AUTOSAR XML (schema 00046)
package /ComponentTypes
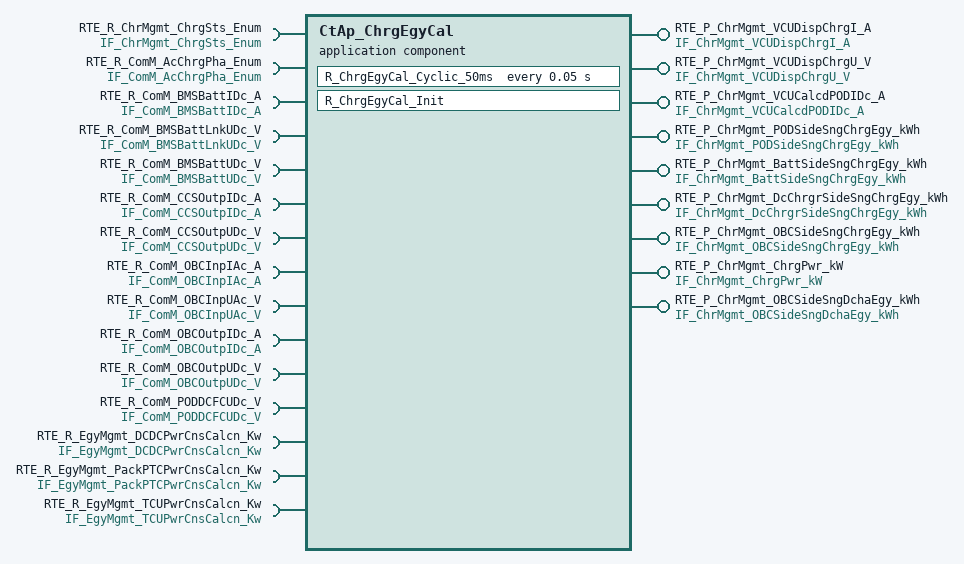
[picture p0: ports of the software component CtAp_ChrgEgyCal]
  application sw component type CtAp_ChrgEgyCal
    9 x provide port:
      RTE_P_ChrMgmt_VCUDispChrgI_A: nonqueued-sender-com-spec{data-element=tec_ChrMgmt_VCUDispChrgI_A, init-value=0}, provided-interface=IF_ChrMgmt_VCUDispChrgI_A
      RTE_P_ChrMgmt_VCUDispChrgU_V: nonqueued-sender-com-spec{data-element=tec_ChrMgmt_VCUDispChrgU_V, init-value=0}, provided-interface=IF_ChrMgmt_VCUDispChrgU_V
      RTE_P_ChrMgmt_VCUCalcdPODIDc_A: nonqueued-sender-com-spec{data-element=tec_ChrMgmt_VCUCalcdPODIDc_A, init-value=0}, provided-interface=IF_ChrMgmt_VCUCalcdPODIDc_A
      RTE_P_ChrMgmt_PODSideSngChrgEgy_kWh: nonqueued-sender-com-spec{data-element=tec_ChrMgmt_PODSideSngChrgEgy_kWh, init-value=0}, provided-interface=IF_ChrMgmt_PODSideSngChrgEgy_kWh
      RTE_P_ChrMgmt_BattSideSngChrgEgy_kWh: nonqueued-sender-com-spec{data-element=tec_ChrMgmt_BattSideSngChrgEgy_kWh, init-value=0}, provided-interface=IF_ChrMgmt_BattSideSngChrgEgy_kWh
      RTE_P_ChrMgmt_DcChrgrSideSngChrgEgy_kWh: nonqueued-sender-com-spec{data-element=tec_ChrMgmt_DcChrgrSideSngChrgEgy_kWh, init-value=0}, provided-interface=IF_ChrMgmt_DcChrgrSideSngChrgEgy_kWh
      RTE_P_ChrMgmt_OBCSideSngChrgEgy_kWh: nonqueued-sender-com-spec{data-element=tec_ChrMgmt_OBCSideSngChrgEgy_kWh, init-value=0}, provided-interface=IF_ChrMgmt_OBCSideSngChrgEgy_kWh
      RTE_P_ChrMgmt_ChrgPwr_kW: nonqueued-sender-com-spec{data-element=tec_ChrMgmt_ChrgPwr_kW, init-value=0}, provided-interface=IF_ChrMgmt_ChrgPwr_kW
      RTE_P_ChrMgmt_OBCSideSngDchaEgy_kWh: nonqueued-sender-com-spec{data-element=tec_ChrMgmt_OBCSideSngDchaEgy_kWh, init-value=0}, provided-interface=IF_ChrMgmt_OBCSideSngDchaEgy_kWh
    15 x require port:
      RTE_R_ChrMgmt_ChrgSts_Enum: nonqueued-receiver-com-spec{data-element=tec_ChrMgmt_ChrgSts_Enum, filter=data-filter-type=ALWAYS, init-value=0}, required-interface=IF_ChrMgmt_ChrgSts_Enum
      RTE_R_ComM_AcChrgPha_Enum: nonqueued-receiver-com-spec{data-element=tec_ComM_AcChrgPha_Enum, filter=data-filter-type=ALWAYS, init-value=0}, required-interface=IF_ComM_AcChrgPha_Enum
      RTE_R_ComM_BMSBattIDc_A: nonqueued-receiver-com-spec{data-element=tec_ComM_BMSBattIDc_A, filter=data-filter-type=ALWAYS, init-value=0}, required-interface=IF_ComM_BMSBattIDc_A
      RTE_R_ComM_BMSBattLnkUDc_V: nonqueued-receiver-com-spec{data-element=tec_ComM_BMSBattLnkUDc_V, filter=data-filter-type=ALWAYS, init-value=0}, required-interface=IF_ComM_BMSBattLnkUDc_V
      RTE_R_ComM_BMSBattUDc_V: nonqueued-receiver-com-spec{data-element=tec_ComM_BMSBattUDc_V, filter=data-filter-type=ALWAYS, init-value=0}, required-interface=IF_ComM_BMSBattUDc_V
      RTE_R_ComM_CCSOutpIDc_A: nonqueued-receiver-com-spec{data-element=tec_ComM_CCSOutpIDc_A, filter=data-filter-type=ALWAYS, init-value=0}, required-interface=IF_ComM_CCSOutpIDc_A
      RTE_R_ComM_CCSOutpUDc_V: nonqueued-receiver-com-spec{data-element=tec_ComM_CCSOutpUDc_V, filter=data-filter-type=ALWAYS, init-value=0}, required-interface=IF_ComM_CCSOutpUDc_V
      RTE_R_ComM_OBCInpIAc_A: nonqueued-receiver-com-spec{data-element=tec_ComM_OBCInpIAc_A, filter=data-filter-type=ALWAYS, init-value=0}, required-interface=IF_ComM_OBCInpIAc_A
      RTE_R_ComM_OBCInpUAc_V: nonqueued-receiver-com-spec{data-element=tec_ComM_OBCInpUAc_V, filter=data-filter-type=ALWAYS, init-value=0}, required-interface=IF_ComM_OBCInpUAc_V
      RTE_R_ComM_OBCOutpIDc_A: nonqueued-receiver-com-spec{data-element=tec_ComM_OBCOutpIDc_A, filter=data-filter-type=ALWAYS, init-value=0}, required-interface=IF_ComM_OBCOutpIDc_A
      RTE_R_ComM_OBCOutpUDc_V: nonqueued-receiver-com-spec{data-element=tec_ComM_OBCOutpUDc_V, filter=data-filter-type=ALWAYS, init-value=0}, required-interface=IF_ComM_OBCOutpUDc_V
      RTE_R_ComM_PODDCFCUDc_V: nonqueued-receiver-com-spec{data-element=tec_ComM_PODDCFCUDc_V, filter=data-filter-type=ALWAYS, init-value=0}, required-interface=IF_ComM_PODDCFCUDc_V
      RTE_R_EgyMgmt_DCDCPwrCnsCalcn_Kw: nonqueued-receiver-com-spec{data-element=tec_EgyMgmt_DCDCPwrCnsCalcn_Kw, filter=data-filter-type=ALWAYS, init-value=0}, required-interface=IF_EgyMgmt_DCDCPwrCnsCalcn_Kw
      RTE_R_EgyMgmt_PackPTCPwrCnsCalcn_Kw: nonqueued-receiver-com-spec{data-element=tec_EgyMgmt_PackPTCPwrCnsCalcn_Kw, filter=data-filter-type=ALWAYS, init-value=0}, required-interface=IF_EgyMgmt_PackPTCPwrCnsCalcn_Kw
      RTE_R_EgyMgmt_TCUPwrCnsCalcn_Kw: nonqueued-receiver-com-spec{data-element=tec_EgyMgmt_TCUPwrCnsCalcn_Kw, filter=data-filter-type=ALWAYS, init-value=0}, required-interface=IF_EgyMgmt_TCUPwrCnsCalcn_Kw
    behavior CtAp_ChrgEgyCal_InternalBehavior
      init event CtAp_ChrgEgyCal_InitEvent: start-on-event=R_ChrgEgyCal_Init
      timing event TMT_R_ChrgEgyCal_Cyclic_50ms: start-on-event=R_ChrgEgyCal_Cyclic_50ms, period=0.05
      runnable R_ChrgEgyCal_Init
      runnable R_ChrgEgyCal_Cyclic_50ms
        data-receive-point-by-arguments:
          15 x access:
            REC_RTE_R_ChrMgmt_ChrgSts_Enum_tec_ChrMgmt_ChrgSts_Enum: accessed-variable=RTE_R_ChrMgmt_ChrgSts_Enum.tec_ChrMgmt_ChrgSts_Enum
            REC_RTE_R_ComM_AcChrgPha_Enum_tec_ComM_AcChrgPha_Enum: accessed-variable=RTE_R_ComM_AcChrgPha_Enum.tec_ComM_AcChrgPha_Enum
            REC_RTE_R_ComM_BMSBattIDc_A_tec_ComM_BMSBattIDc_A: accessed-variable=RTE_R_ComM_BMSBattIDc_A.tec_ComM_BMSBattIDc_A
            REC_RTE_R_ComM_BMSBattLnkUDc_V_tec_ComM_BMSBattLnkUDc_V: accessed-variable=RTE_R_ComM_BMSBattLnkUDc_V.tec_ComM_BMSBattLnkUDc_V
            REC_RTE_R_ComM_BMSBattUDc_V_tec_ComM_BMSBattUDc_V: accessed-variable=RTE_R_ComM_BMSBattUDc_V.tec_ComM_BMSBattUDc_V
            REC_RTE_R_ComM_CCSOutpIDc_A_tec_ComM_CCSOutpIDc_A: accessed-variable=RTE_R_ComM_CCSOutpIDc_A.tec_ComM_CCSOutpIDc_A
            REC_RTE_R_ComM_CCSOutpUDc_V_tec_ComM_CCSOutpUDc_V: accessed-variable=RTE_R_ComM_CCSOutpUDc_V.tec_ComM_CCSOutpUDc_V
            REC_RTE_R_ComM_OBCInpIAc_A_tec_ComM_OBCInpIAc_A: accessed-variable=RTE_R_ComM_OBCInpIAc_A.tec_ComM_OBCInpIAc_A
            REC_RTE_R_ComM_OBCInpUAc_V_tec_ComM_OBCInpUAc_V: accessed-variable=RTE_R_ComM_OBCInpUAc_V.tec_ComM_OBCInpUAc_V
            REC_RTE_R_ComM_OBCOutpIDc_A_tec_ComM_OBCOutpIDc_A: accessed-variable=RTE_R_ComM_OBCOutpIDc_A.tec_ComM_OBCOutpIDc_A
            REC_RTE_R_ComM_OBCOutpUDc_V_tec_ComM_OBCOutpUDc_V: accessed-variable=RTE_R_ComM_OBCOutpUDc_V.tec_ComM_OBCOutpUDc_V
            REC_RTE_R_ComM_PODDCFCUDc_V_tec_ComM_PODDCFCUDc_V: accessed-variable=RTE_R_ComM_PODDCFCUDc_V.tec_ComM_PODDCFCUDc_V
            REC_RTE_R_EgyMgmt_DCDCPwrCnsCalcn_Kw_tec_EgyMgmt_DCDCPwrCnsCalcn_Kw: accessed-variable=RTE_R_EgyMgmt_DCDCPwrCnsCalcn_Kw.tec_EgyMgmt_DCDCPwrCnsCalcn_Kw
            REC_RTE_R_EgyMgmt_PackPTCPwrCnsCalcn_Kw_tec_EgyMgmt_PackPTCPwrCnsCalcn_Kw: accessed-variable=RTE_R_EgyMgmt_PackPTCPwrCnsCalcn_Kw.tec_EgyMgmt_PackPTCPwrCnsCalcn_Kw
            REC_RTE_R_EgyMgmt_TCUPwrCnsCalcn_Kw_tec_EgyMgmt_TCUPwrCnsCalcn_Kw: accessed-variable=RTE_R_EgyMgmt_TCUPwrCnsCalcn_Kw.tec_EgyMgmt_TCUPwrCnsCalcn_Kw
        data-send-points:
          9 x access:
            SEND_RTE_P_ChrMgmt_BattSideSngChrgEgy_kWh_tec_ChrMgmt_BattSideSngChrgEgy_kWh: accessed-variable=RTE_P_ChrMgmt_BattSideSngChrgEgy_kWh.tec_ChrMgmt_BattSideSngChrgEgy_kWh
            SEND_RTE_P_ChrMgmt_ChrgPwr_kW_tec_ChrMgmt_ChrgPwr_kW: accessed-variable=RTE_P_ChrMgmt_ChrgPwr_kW.tec_ChrMgmt_ChrgPwr_kW
            SEND_RTE_P_ChrMgmt_DcChrgrSideSngChrgEgy_kWh_tec_ChrMgmt_DcChrgrSideSngChrgEgy_kWh: accessed-variable=RTE_P_ChrMgmt_DcChrgrSideSngChrgEgy_kWh.tec_ChrMgmt_DcChrgrSideSngChrgEgy_kWh
            SEND_RTE_P_ChrMgmt_OBCSideSngChrgEgy_kWh_tec_ChrMgmt_OBCSideSngChrgEgy_kWh: accessed-variable=RTE_P_ChrMgmt_OBCSideSngChrgEgy_kWh.tec_ChrMgmt_OBCSideSngChrgEgy_kWh
            SEND_RTE_P_ChrMgmt_OBCSideSngDchaEgy_kWh_tec_ChrMgmt_OBCSideSngDchaEgy_kWh: accessed-variable=RTE_P_ChrMgmt_OBCSideSngDchaEgy_kWh.tec_ChrMgmt_OBCSideSngDchaEgy_kWh
            SEND_RTE_P_ChrMgmt_PODSideSngChrgEgy_kWh_tec_ChrMgmt_PODSideSngChrgEgy_kWh: accessed-variable=RTE_P_ChrMgmt_PODSideSngChrgEgy_kWh.tec_ChrMgmt_PODSideSngChrgEgy_kWh
            SEND_RTE_P_ChrMgmt_VCUCalcdPODIDc_A_tec_ChrMgmt_VCUCalcdPODIDc_A: accessed-variable=RTE_P_ChrMgmt_VCUCalcdPODIDc_A.tec_ChrMgmt_VCUCalcdPODIDc_A
            SEND_RTE_P_ChrMgmt_VCUDispChrgI_A_tec_ChrMgmt_VCUDispChrgI_A: accessed-variable=RTE_P_ChrMgmt_VCUDispChrgI_A.tec_ChrMgmt_VCUDispChrgI_A
            SEND_RTE_P_ChrMgmt_VCUDispChrgU_V_tec_ChrMgmt_VCUDispChrgU_V: accessed-variable=RTE_P_ChrMgmt_VCUDispChrgU_V.tec_ChrMgmt_VCUDispChrgU_V
  swc implementation CtAp_ChrgEgyCal_Implementation: behavior=CtAp_ChrgEgyCal_InternalBehavior
    code-descriptors:
      code Default: artifact-descriptors=autosar-engineering-object=category=SWOBJ
